# NM1120AE_v1 register map
File version: 1.0
Registers are 32-bit, read-write, reset 0x0 unless marked. A register's access mark holds for its fields unless they carry their own. Offsets are from the block's base; [hi:lo] are bit positions; 'fields as' and 'values as' point back to an identical list.

## ACMP — ACMP Register Map
Base 0x400D0000
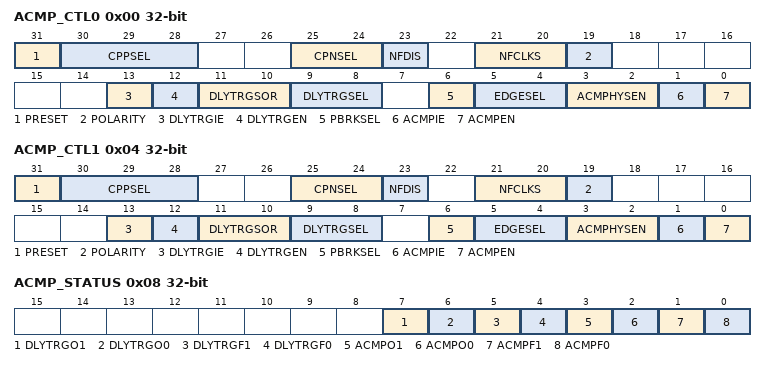
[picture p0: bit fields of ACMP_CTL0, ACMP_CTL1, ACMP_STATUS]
0x00 ACMP_CTL0 — Analog Comparator0 Control Register
  [31] PRESET — Comparator Result Preset Value
    0=0 for preset value; 1=1 for preset value
  [30:28] CPPSEL — Comparator Positive Input Select
    0=ACMP0_P0 (PB.0); 1=ACMP0_P1 (PB.1); 2=ACMP0_P2 (PB.2); 3=ACMP0_P3 (PC.1); 4=PGA_CMP
  [25:24] CPNSEL — Comparator Negative Input Select
    0=ACMP0_N (PB.4); 1=Band_Gap; 2=CRV
  [23] NFDIS — Disable Comparator Noise Filter
    0=Noise filter Enabled; 1=Noise filter Disabled
  [21:20] NFCLKS — Noise Filter Clock Pre-divided Selection. To determine the sampling frequency of the Noise Filter clock
    0=PCLK; 1=PCLK / 2; 2=PCLK / 4; 3=PCLK / 16
  [19] POLARITY — Analog Comparator Polarity Control
    0=Analog Comparator normal output; 1=Analog Comparator invert output
  [13] DLYTRGIE — Analog Comparator Delay Trigger Mode Interrupt Enable Control
    0=Analog Comparator Delay Trigger Mode Interrupt Disabled; 1=Analog Comparator Delay Trigger Mode Interrupt Enabled
  [12] DLYTRGEN — Analog Comparator Delay Trigger Mode Enable Control
    0=Analog Comparator Delay Trigger Mode Disabled; 1=Analog Comparator Delay Trigger Mode Enabled
  [11:10] DLYTRGSOR — Analog Comparator Delay Trigger Mode Trigger Source Selection
    0=PWM0; 1=PWM2; 2=PWM4
  [9:8] DLYTRGSEL — Analog Comparator Delay Trigger Mode Trigger Level Selection
    0=Analog Comparator Delay Trigger Mode Trigger Disabled; 1=Rising; 2=Falling; 3=Rising/Falling
  [6] PBRKSEL — ACMP to EPWM Brake Selection
    0=ACMP Result direct output; 1=ACMP Delay Trigger Result output
  [5:4] EDGESEL — Interrupt Flag Trigger Edge Detection
    0=Interrupt Flag Trigger Edge Disabled; 1=Rising; 2=Falling; 3=Rising/Falling
  [3:2] ACMPHYSEN — Comparator0 Hysteresis Enable Control (Only 20mV)
    0=ACMP0 Hysteresis function Disabled (Default); 1=ACMP0 Hysteresis function at comparator 0 Enabled that the typical range is 10mV; 2=ACMP0 Hysteresis function at comparator 0 Enabled that the typical range is 90mV; 3=ACMP0 Hysteresis function Disabled
  [1] ACMPIE — Comparator Interrupt Enable Control. Note1: Interrupt is generated if ACMPIE bit is set to "1" after ACMP conversion is finished. Note2: ACMP interrupt will wake CPU up in Power-down mode.
    0=ACMP interrupt function Disabled; 1=ACMP interrupt function Enabled
  [0] ACMPEN — Comparator Enable Control. Note: Comparator output needs to wait 2 us stable time after ACMPEN is set.
    0=Comparator Disabled; 1=Comparator Enabled
0x04 ACMP_CTL1 — Analog Comparator1 Control Register
  [31] PRESET — Comparator Result Preset Value
    0=0 for preset value; 1=1 for preset value
  [30:28] CPPSEL — Comparator Positive Input Selection
    0=ACMP1_P0 (PC.0); 1=ACMP1_P1 (PC.1); 2=ACMP1_P2 (PD.1); 3=PGA_CMP
  [25:24] CPNSEL — Comparator Negative Input Selection
    0=ACMP1_N (PB.3); 1=Band_Gap; 2=CRV
  [23] NFDIS — Disable Comparator Noise Filter
    0=Noise filter Enable; 1=Noise filter Disable
  [21:20] NFCLKS — Noise Filter Clock Pre-divided Selection. To determine the sampling frequency of the Noise Filter clock
    0=PCLK; 1=PCLK / 2; 2=PCLK / 4; 3=PCLK / 16
  [19] POLARITY — Analog Comparator Polarity Control
    values as ACMP_CTL0.POLARITY
  [13] DLYTRGIE — Analog Comparator Delay Trigger Mode Interrupt Enable
    values as ACMP_CTL0.DLYTRGIE
  [12] DLYTRGEN — Analog Comparator Delay Trigger Mode Enable
    values as ACMP_CTL0.DLYTRGEN
  [11:10] DLYTRGSOR — Analog Comparator Delay Trigger Mode Trigger Source Selection
    0=PWM0; 1=PWM2; 2=PWM4
  [9:8] DLYTRGSEL — Analog Comparator Delay Trigger Mode Trigger Level Selection
    values as ACMP_CTL0.DLYTRGSEL
  [6] PBRKSEL — ACMP to EPWM Brake Selection
    values as ACMP_CTL0.PBRKSEL
  [5:4] EDGESEL — Interrupt Flag Trigger Edge Detection
    0=Interrupt Flag Trigger Edge Detection Disable; 1=Rising; 2=Falling; 3=Rising/Falling
  [3:2] ACMPHYSEN — Comparator1 Hysteresis Enable Control (Only 20mV)
    values as ACMP_CTL0.ACMPHYSEN
  [1] ACMPIE — Comparator Interrupt Enable Control. Note1: Interrupt is generated if ACMPIE bit is set to "1" after ACMP conversion is finished. Note2: ACMP interrupt will wake CPU up in Power-down mode.
    values as ACMP_CTL0.ACMPIE
  [0] ACMPEN — Comparator Enable Control. Note: Comparator output needs to wait 2 us stable time after ACMPEN is set.
    0=Comparator Disabled; 1=Comparator Enabled
0x08 ACMP_STATUS — Analog Comparator Status Register
  [7] DLYTRGO1 — Analog Comparator1 Delay Trigger Mode Comparator Output
  [6] DLYTRGO0 — Analog Comparator0 Delay Trigger Mode Comparator Output
  [5] DLYTRGF1 — Comparator1 Flag. This bit is set by hardware whenever the comparator1 output changes state. This will cause an interrupt if DLYTRGIEN set. Write "1" to clear this bit to 0.
  [4] DLYTRGF0 — Comparator0 Flag. This bit is set by hardware whenever the comparator0 output changes state. This will cause an interrupt if DLYTRGIEN set. Write "1" to clear this bit to 0.
  [3] ACMPO1 — Comparator1 Output
  [2] ACMPO0 — Comparator0 Output
  [1] ACMPF1 — Comparator1 Flag. This bit is set by hardware whenever the comparator1 output changes state. This will cause an interrupt if ACMPIE set. Write "1" to clear this bit to 0.
  [0] ACMPF0 — Comparator0 Flag. This bit is set by hardware whenever the comparator0 output changes state. This will cause an interrupt if ACMPIE set. Write "1" to clear this bit to 0.
0x0C ACMP_VREF — Analog Comparator Reference Voltage Control Register
  [3:0] CRVCTL — Comparator Reference Voltage Setting
0x10 ACMP_TRGDLY — Analog Comparator Delay Trigger Mode Dleay Register
  [8:0] DELAY — Analog Comparator Delay Trigger Mode Dleay cycle
